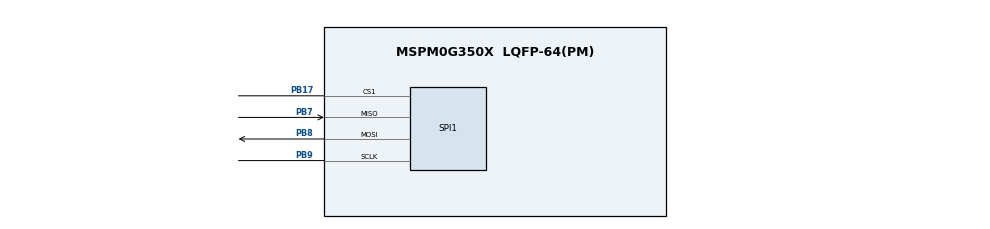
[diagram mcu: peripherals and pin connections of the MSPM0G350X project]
/**
 * @cliArgs --device "MSPM0G350X" --part "Default" --package "LQFP-64(PM)" --product "mspm0_sdk@2.02.00.05"
 * @versions {"tool":"1.21.0+3721"}
 */

/**
 * Import the modules used in this configuration.
 */
const GPIO   = scripting.addModule("/ti/driverlib/GPIO", {}, false);
const GPIO1  = GPIO.addInstance();
const SPI    = scripting.addModule("/ti/driverlib/SPI", {}, false);
const SPI1   = SPI.addInstance();
const SYSCTL = scripting.addModule("/ti/driverlib/SYSCTL");

/**
 * Write custom configuration values to the imported modules.
 */
GPIO1.$name                          = "GPIO_GRP_0";
GPIO1.associatedPins[0].$name        = "k1";
GPIO1.associatedPins[0].direction    = "INPUT";
GPIO1.associatedPins[0].assignedPort = "PORTA";
GPIO1.associatedPins[0].assignedPin  = "18";
GPIO1.associatedPins[0].interruptEn  = true;
GPIO1.associatedPins[0].polarity     = "RISE";

const Board = scripting.addModule("/ti/driverlib/Board", {}, false);

SPI1.$name                      = "SPI_0";
SPI1.targetBitRate              = 500000;
SPI1.chipSelect                 = ["1"];
SPI1.enabledInterrupts          = ["RX"];
SPI1.peripheral.$assign         = "SPI1";
SPI1.peripheral.sclkPin.$assign = "PB9";
SPI1.peripheral.mosiPin.$assign = "PB8";
SPI1.peripheral.misoPin.$assign = "PB7";
SPI1.peripheral.cs1Pin.$assign  = "PB17";
SPI1.sclkPinConfig.$name        = "ti_driverlib_gpio_GPIOPinGeneric0";
SPI1.mosiPinConfig.$name        = "ti_driverlib_gpio_GPIOPinGeneric1";
SPI1.misoPinConfig.$name        = "ti_driverlib_gpio_GPIOPinGeneric2";
SPI1.cs1PinConfig.$name         = "ti_driverlib_gpio_GPIOPinGeneric4";

SYSCTL.forceDefaultClkConfig = true;

/**
 * Pinmux solution for unlocked pins/peripherals. This ensures that minor changes to the automatic solver in a future
 * version of the tool will not impact the pinmux you originally saw.  These lines can be completely deleted in order to
 * re-solve from scratch.
 */
GPIO1.associatedPins[0].pin.$suggestSolution = "PA18";
Board.peripheral.$suggestSolution            = "DEBUGSS";
Board.peripheral.swclkPin.$suggestSolution   = "PA20";
Board.peripheral.swdioPin.$suggestSolution   = "PA19";
SYSCTL.peripheral.$suggestSolution           = "SYSCTL";
